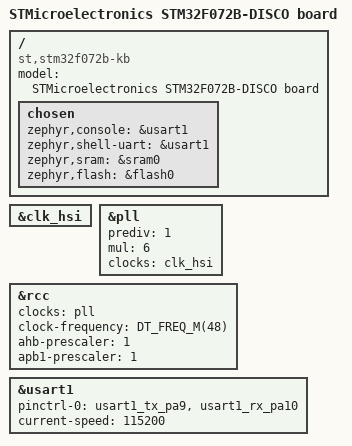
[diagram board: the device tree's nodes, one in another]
/*
 * Copyright (c) 2017 Clage GmbH
 *
 * SPDX-License-Identifier: Apache-2.0
 */

/dts-v1/;
#include <st/f0/stm32f072Xb.dtsi>
#include <st/f0/stm32f072c(8-b)ux-pinctrl.dtsi>

/ {
	model = "STMicroelectronics STM32F072B-DISCO board";
	compatible = "st,stm32f072b-kb";

	chosen {
		zephyr,console = &usart1;
		zephyr,shell-uart = &usart1;
		zephyr,sram = &sram0;
		zephyr,flash = &flash0;
	};
};

&clk_hsi {
	status = "okay";
};

&pll {
	prediv = <1>;
	mul = <6>;
	clocks = <&clk_hsi>;
	status = "okay";
};

&rcc {
	clocks = <&pll>;
	clock-frequency = <DT_FREQ_M(48)>;
	ahb-prescaler = <1>;
	apb1-prescaler = <1>;
};

&usart1 {
	pinctrl-0 = <&usart1_tx_pa9 &usart1_rx_pa10>;
	pinctrl-names = "default";
	current-speed = <115200>;
	status = "okay";
};
